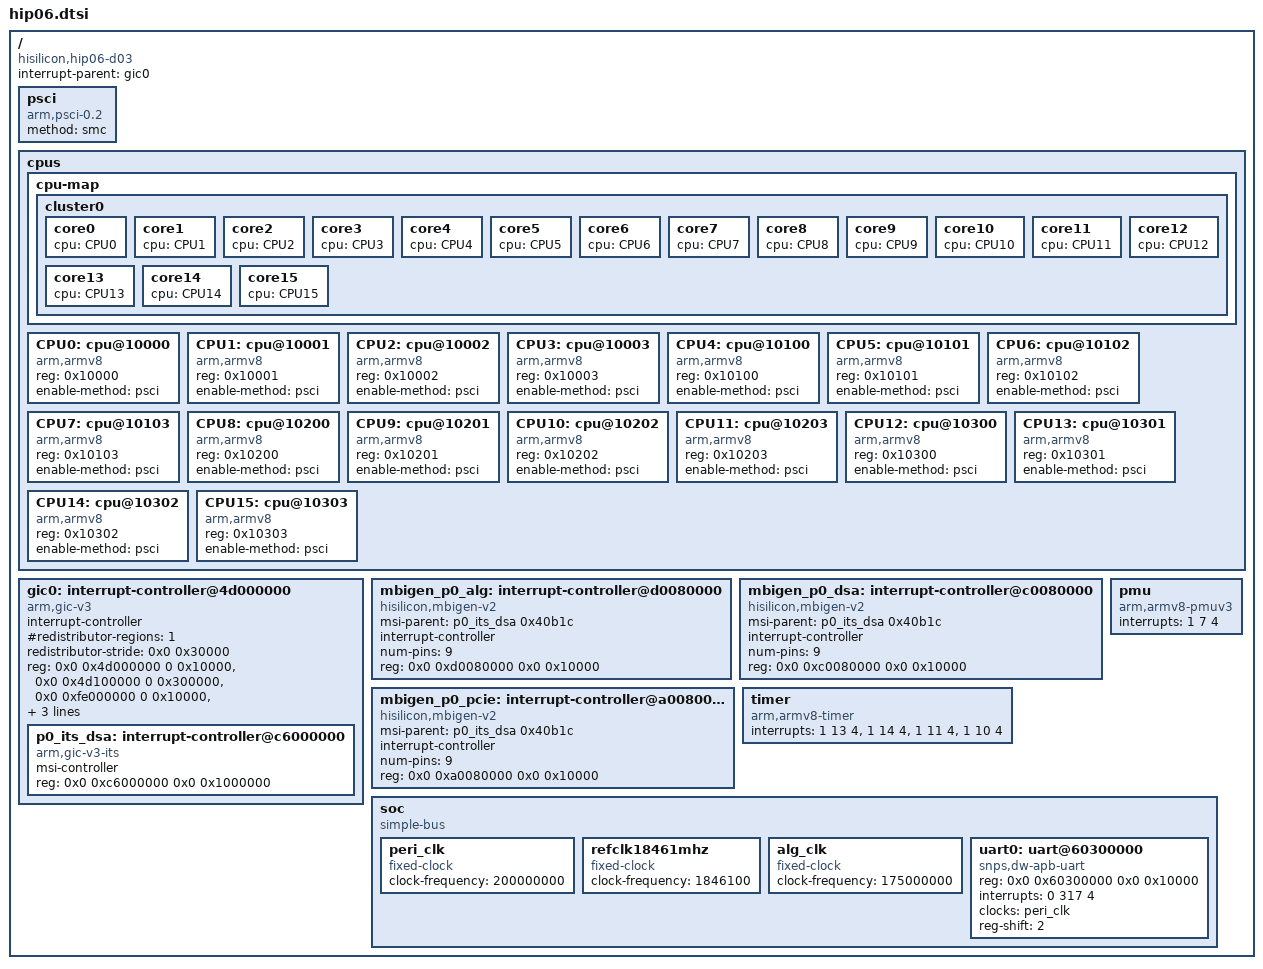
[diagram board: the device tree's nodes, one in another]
/**
 * dts file for Hisilicon D03 Development Board
 *
 * Copyright (C) 2014,2015 Hisilicon Ltd.
 *
 * This program is free software; you can redistribute it and/or modify
 * it under the terms of the GNU General Public License version 2 as
 * publishhed by the Free Software Foundation.
 *
 */

/ {
	#address-cells = <2>;
	#size-cells = <2>;
	compatible = "hisilicon,hip06-d03";
	interrupt-parent = <&gic0>;

	psci {
		compatible = "arm,psci-0.2";
		method = "smc";
	};

	cpus {
		#address-cells = <1>;
		#size-cells = <0>;

		cpu-map {
			cluster0 {
				core0 {
					cpu = <&CPU0>;
				};

				core1 {
					cpu = <&CPU1>;
				};

				core2 {
					cpu = <&CPU2>;
				};

				core3 {
					cpu = <&CPU3>;
				};

				core4 {
					cpu = <&CPU4>;
				};

				core5 {
					cpu = <&CPU5>;
				};

				core6 {
					cpu = <&CPU6>;
				};

				core7 {
					cpu = <&CPU7>;
				};

				core8 {
					cpu = <&CPU8>;
				};

				core9 {
					cpu = <&CPU9>;
				};

				core10 {
					cpu = <&CPU10>;
				};

				core11 {
					cpu = <&CPU11>;
				};

				core12 {
					cpu = <&CPU12>;
				};

				core13 {
					cpu = <&CPU13>;
				};

				core14 {
					cpu = <&CPU14>;
				};

				core15 {
					cpu = <&CPU15>;
				};
			};
		};

		CPU0: cpu@10000 {
			device_type = "cpu";
			compatible = "arm,armv8";
			reg = <0x10000>;
			enable-method = "psci";
		};

		CPU1: cpu@10001 {
			device_type = "cpu";
			compatible = "arm,armv8";
			reg = <0x10001>;
			enable-method = "psci";
		};

		CPU2: cpu@10002 {
			device_type = "cpu";
			compatible = "arm,armv8";
			reg = <0x10002>;
			enable-method = "psci";
		};

		CPU3: cpu@10003 {
			device_type = "cpu";
			compatible = "arm,armv8";
			reg = <0x10003>;
			enable-method = "psci";
		};

		CPU4: cpu@10100 {
			device_type = "cpu";
			compatible = "arm,armv8";
			reg = <0x10100>;
			enable-method = "psci";
		};

		CPU5: cpu@10101 {
			device_type = "cpu";
			compatible = "arm,armv8";
			reg = <0x10101>;
			enable-method = "psci";
		};

		CPU6: cpu@10102 {
			device_type = "cpu";
			compatible = "arm,armv8";
			reg = <0x10102>;
			enable-method = "psci";
		};

		CPU7: cpu@10103 {
			device_type = "cpu";
			compatible = "arm,armv8";
			reg = <0x10103>;
			enable-method = "psci";
		};

		CPU8: cpu@10200 {
			device_type = "cpu";
			compatible = "arm,armv8";
			reg = <0x10200>;
			enable-method = "psci";
		};

		CPU9: cpu@10201 {
			device_type = "cpu";
			compatible = "arm,armv8";
			reg = <0x10201>;
			enable-method = "psci";
		};

		CPU10: cpu@10202 {
			device_type = "cpu";
			compatible = "arm,armv8";
			reg = <0x10202>;
			enable-method = "psci";
		};

		CPU11: cpu@10203 {
			device_type = "cpu";
			compatible = "arm,armv8";
			reg = <0x10203>;
			enable-method = "psci";
		};

		CPU12: cpu@10300 {
			device_type = "cpu";
			compatible = "arm,armv8";
			reg = <0x10300>;
			enable-method = "psci";
		};

		CPU13: cpu@10301 {
			device_type = "cpu";
			compatible = "arm,armv8";
			reg = <0x10301>;
			enable-method = "psci";
		};

		CPU14: cpu@10302 {
			device_type = "cpu";
			compatible = "arm,armv8";
			reg = <0x10302>;
			enable-method = "psci";
		};

		CPU15: cpu@10303 {
			device_type = "cpu";
			compatible = "arm,armv8";
			reg = <0x10303>;
			enable-method = "psci";
		};
	};

	gic0: interrupt-controller@4d000000 {
		compatible = "arm,gic-v3";
		#interrupt-cells = <3>;
		#address-cells = <2>;
		#size-cells = <2>;
		ranges;
		interrupt-controller;
		#redistributor-regions = <1>;
		redistributor-stride = <0x0 0x30000>;
		reg = <0x0 0x4d000000 0 0x10000>,	/* GICD */
		      <0x0 0x4d100000 0 0x300000>,	/* GICR */
		      <0x0 0xfe000000 0 0x10000>,	/* GICC */
		      <0x0 0xfe010000 0 0x10000>,	/* GICH */
		      <0x0 0xfe020000 0 0x10000>;	/* GICV */

		interrupts = <1 9 0xff04>;

		p0_its_dsa: interrupt-controller@c6000000 {
			compatible = "arm,gic-v3-its";
			msi-controller;
			#msi-cells = <1>;
			reg = <0x0 0xc6000000 0x0 0x1000000>;
		};
	};

	mbigen_p0_alg: interrupt-controller@d0080000 {
		compatible = "hisilicon,mbigen-v2";
		msi-parent = <&p0_its_dsa 0x40b1c>;
		interrupt-controller;
		#interrupt-cells = <2>;
		num-pins = <9>;
		reg = <0x0 0xd0080000 0x0 0x10000>;
	};

	mbigen_p0_dsa: interrupt-controller@c0080000 {
		compatible = "hisilicon,mbigen-v2";
		msi-parent = <&p0_its_dsa 0x40b1c>;
		interrupt-controller;
		#interrupt-cells = <2>;
		num-pins = <9>;
		reg = <0x0 0xc0080000 0x0 0x10000>;
	};

	mbigen_p0_pcie: interrupt-controller@a0080000 {
		compatible = "hisilicon,mbigen-v2";
		msi-parent = <&p0_its_dsa 0x40b1c>;
		interrupt-controller;
		#interrupt-cells = <2>;
		num-pins = <9>;
		reg = <0x0 0xa0080000 0x0 0x10000>;
	};

	timer {
		compatible = "arm,armv8-timer";
		interrupts = <1 13 4>,
			     <1 14 4>,
			     <1 11 4>,
			     <1 10 4>;
	};

	pmu {
		compatible = "arm,armv8-pmuv3";
		interrupts = <1 7 4>;
	};

	soc {
		compatible = "simple-bus";
		#address-cells = <2>;
		#size-cells = <2>;
		ranges = <0x0 0x0 0x0 0x0 0xfff 0xffffffff>;

		peri_clk: peri_clk {
			compatible = "fixed-clock";
			#clock-cells = <0>;
			clock-frequency = <200000000>;
		};

		refclk18461mhz: refclk18461mhz {
			compatible = "fixed-clock";
			#clock-cells = <0>;
			clock-frequency = <1846100>;
		};

		alg_clk: alg_clk {
			compatible = "fixed-clock";
			#clock-cells = <0>;
			clock-frequency = <175000000>;
		};

		uart0: uart@60300000 {
			compatible = "snps,dw-apb-uart";
			reg = <0x0 0x60300000 0x0 0x10000>;
			interrupts = <0 317 4>;
			clocks = <&peri_clk>;
			clock-names = "apb_pclk";
			reg-shift = <2>;
		};
	};
};
